# EFR32BG13P532F512GM32 register map
File version: 5.8.2
CPU: CM4 r0p1, little endian, MPU, FPU, 3 interrupt priority bits
Registers are 32-bit, read-write, reset 0x0 unless marked. A register's access mark holds for its fields unless they carry their own. Offsets are from the block's base; [hi:lo] are bit positions.

## FPUEH
Base 0x400E1000
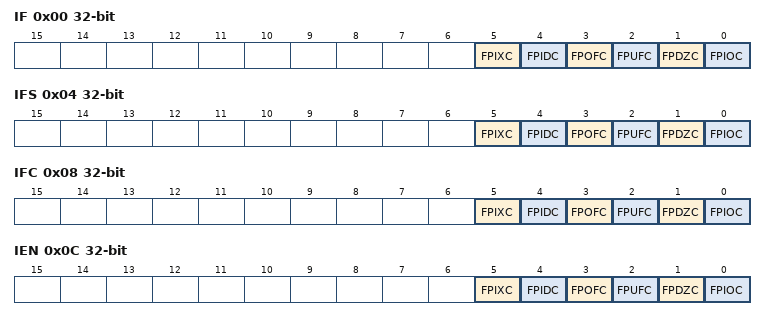
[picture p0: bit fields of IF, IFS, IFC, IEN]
0x00 IF ro — Interrupt Flag Register
  [5] FPIXC — FPU inexact exception
  [4] FPIDC — FPU input denormal exception
  [3] FPOFC — FPU overflow exception
  [2] FPUFC — FPU underflow exception
  [1] FPDZC — FPU divide-by-zero exception
  [0] FPIOC — FPU invalid operation
0x04 IFS wo — Interrupt Flag Set Register
  [5] FPIXC — Set FPIXC Interrupt Flag
  [4] FPIDC — Set FPIDC Interrupt Flag
  [3] FPOFC — Set FPOFC Interrupt Flag
  [2] FPUFC — Set FPUFC Interrupt Flag
  [1] FPDZC — Set FPDZC Interrupt Flag
  [0] FPIOC — Set FPIOC Interrupt Flag
0x08 IFC wo — Interrupt Flag Clear Register
  [5] FPIXC — Clear FPIXC Interrupt Flag
  [4] FPIDC — Clear FPIDC Interrupt Flag
  [3] FPOFC — Clear FPOFC Interrupt Flag
  [2] FPUFC — Clear FPUFC Interrupt Flag
  [1] FPDZC — Clear FPDZC Interrupt Flag
  [0] FPIOC — Clear FPIOC Interrupt Flag
0x0C IEN — Interrupt Enable Register
  [5] FPIXC — FPIXC Interrupt Enable
  [4] FPIDC — FPIDC Interrupt Enable
  [3] FPOFC — FPOFC Interrupt Enable
  [2] FPUFC — FPUFC Interrupt Enable
  [1] FPDZC — FPDZC Interrupt Enable
  [0] FPIOC — FPIOC Interrupt Enable

## GPCRC
Base 0x4001C000
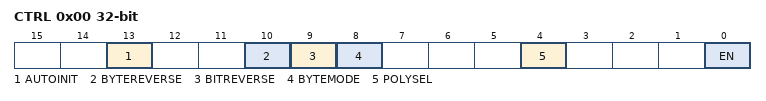
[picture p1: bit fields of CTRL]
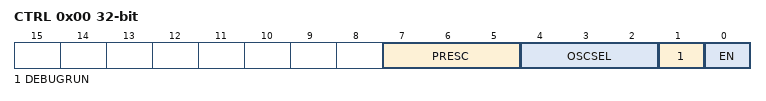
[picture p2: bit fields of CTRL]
0x00 CTRL — Control Register
  [13] AUTOINIT — Auto Init Enable
  [10] BYTEREVERSE — Byte Reverse Mode
  [9] BITREVERSE — Byte-level Bit Reverse Enable
  [8] BYTEMODE — Byte Mode Enable
  [4] POLYSEL — Polynomial Select
  [0] EN — CRC Functionality Enable
0x04 CMD wo — Command Register
  [0] INIT — Initialization Enable
0x08 INIT — CRC Init Value
  [31:0] INIT — CRC Initialization Value
0x0C POLY — CRC Polynomial Value
  [15:0] POLY
0x10 INPUTDATA — Input 32-bit Data Register
  [31:0] INPUTDATA — Input Data for 32-bit
0x14 INPUTDATAHWORD — Input 16-bit Data Register
  [15:0] INPUTDATAHWORD — Input Data for 16-bit
0x18 INPUTDATABYTE — Input 8-bit Data Register
  [7:0] INPUTDATABYTE — Input Data for 8-bit
0x1C DATA ro — CRC Data Register
0x20 DATAREV ro — CRC Data Reverse Register
  [31:0] DATAREV — Data Reverse Value
0x24 DATABYTEREV ro — CRC Data Byte Reverse Register
  [31:0] DATABYTEREV — Data Byte Reverse Value

## CRYOTIMER
Base 0x4001E000
0x00 CTRL — Control Register
  [7:5] PRESC — Prescaler Setting
    0=DIV1 (LF Oscillator frequency undivided); 1=DIV2 (LF Oscillator frequency divided by 2); 2=DIV4 (LF Oscillator frequency divided by 4); 3=DIV8 (LF Oscillator frequency divided by 8); 4=DIV16 (LF Oscillator frequency divided by 16); 5=DIV32 (LF Oscillator frequency divided by 32); 6=DIV64 (LF Oscillator frequency divided by 64); 7=DIV128 (LF Oscillator frequency divided by 128)
  [4:2] OSCSEL — Select Low Frequency Oscillator
    0=DISABLED (Output is driven low); 1=LFRCO (Select Low Frequency RC Oscillator); 2=LFXO (Select Low Frequency Crystal Oscillator); 3=ULFRCO (Select Ultra Low Frequency RC Oscillator)
  [1] DEBUGRUN — Debug Mode Run Enable
  [0] EN — Enable CRYOTIMER
0x04 PERIODSEL reset 0x20 — Interrupt Duration
  [5:0] PERIODSEL — Interrupts/Wakeup Events Period Setting
0x08 CNT ro — Counter Value
0x0C EM4WUEN — Wake Up Enable
  [0] EM4WU — EM4 Wake-up Enable
0x10 IF ro — Interrupt Flag Register
  [0] PERIOD — Wakeup Event/Interrupt
0x14 IFS wo — Interrupt Flag Set Register
  [0] PERIOD — Set PERIOD Interrupt Flag
0x18 IFC wo — Interrupt Flag Clear Register
  [0] PERIOD — Clear PERIOD Interrupt Flag
0x1C IEN — Interrupt Enable Register
  [0] PERIOD — PERIOD Interrupt Enable

## PRORTC
Base 0x40044000
0x00 CTRL — Control Register
  [31:0] UNKNOWN — PRORTC CTRL
0x04 CNT — Counter Value Register
  [31:0] CNT — Counter Value
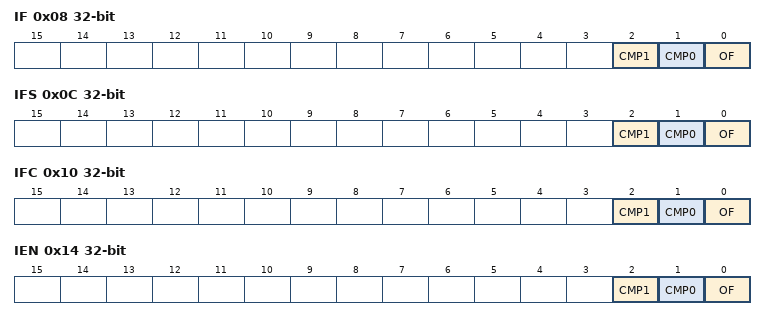
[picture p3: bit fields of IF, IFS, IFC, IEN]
0x08 IF ro (reset mask 0x3) — PRORTC Interrupt Flags
  [2] CMP1 — Compare 1 Interrupt Flag
  [1] CMP0 — Compare 0 Interrupt Flag
  [0] OF — Overflow Interrupt Flag
0x0C IFS wo (reset mask 0x3) — Interrupt Flag Set Register
  [2] CMP1 rw — Set Compare 1 Interrupt Flag
  [1] CMP0 rw — Set Compare 0 Interrupt Flag
  [0] OF ro — Set Overflow Interrupt Flag
0x10 IFC wo (reset mask 0x3) — Interrupt Flag Clear Register
  [2] CMP1 rw — Clear Compare 1 Interrupt Flag
  [1] CMP0 rw — Clear Compare 0 Interrupt Flag
  [0] OF rw — Clear Overflow Interrupt Flag
0x14 IEN (reset mask 0x3) — Interrupt Enable Register
  [2] CMP1 — CMP1 Interrupt Enabled
  [1] CMP0 — CMP0 Interrupt Enabled
  [0] OF — OF Interrupt Enabled
0x20 CMP0 — Compare Value 0 Register
  [31:0] VALUE — Compare Value
0x24 CMP1 — Compare Value 1 Register
  [31:0] VALUE — Compare Value
